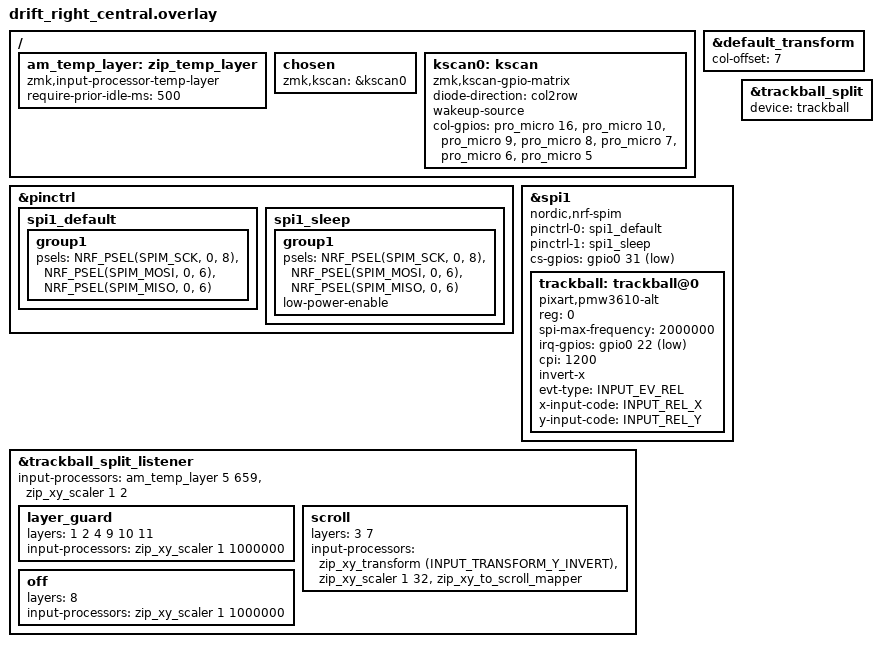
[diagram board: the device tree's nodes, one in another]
// Copyright (c) 2025 The ZMK Contributors
// SPDX-License-Identifier: MIT

#include "drift.dtsi"
#include <input/processors.dtsi>
#include <dt-bindings/zmk/input_transform.h>
#include <dt-bindings/zmk/matrix_transform.h>
//#include <behaviors/input_gestures_accel.dtsi>

// Apply default transform with a column offset (shifts matrix alignment)
&default_transform {
	col-offset = <7>;
};

&pinctrl {
    spi1_default: spi1_default { // Normal SPI operation pins
        group1 {
            psels = <NRF_PSEL(SPIM_SCK, 0, 8)>,
                    <NRF_PSEL(SPIM_MOSI, 0, 6)>,
                    <NRF_PSEL(SPIM_MISO, 0, 6)>;
        };
    };

    // Low-power SPI configuration for sleep mode
    spi1_sleep: spi1_sleep {
        group1 {
            psels = <NRF_PSEL(SPIM_SCK, 0, 8)>,
                    <NRF_PSEL(SPIM_MOSI, 0, 6)>,
                    <NRF_PSEL(SPIM_MISO, 0, 6)>;
            low-power-enable; // reduces power when idle
        };
    };
};

#include <zephyr/dt-bindings/input/input-event-codes.h>

&spi1 {                                     // input device node (SPI)
    status = "okay";                        // keep SPI on
    compatible = "nordic,nrf-spim";
    pinctrl-0 = <&spi1_default>;            // default pins
    pinctrl-1 = <&spi1_sleep>;              // sleep pins
    pinctrl-names = "default", "sleep";
    cs-gpios = <&gpio0 31 GPIO_ACTIVE_LOW>; // chip select for SPI

    trackball: trackball@0 {
        status = "okay";
        compatible = "pixart,pmw3610-alt";
        reg = <0>;                                                // first SPI slave device
        spi-max-frequency = <2000000>;                            // 2 MHz max SPI frequency
        irq-gpios = <&gpio0 22 (GPIO_ACTIVE_LOW | GPIO_PULL_UP)>; // interrupt pin
        cpi = <1200>;                                             // trackball CPI (steps of 200, min 200)
                                                                  // halved back to 600-equivalent speed by the
                                                                  // zip_xy_scaler below; raising CPI alone just
                                                                  // makes the pointer faster, the pair is what
                                                                  // buys finer steps at the same speed
		// swap-xy;                                               // optional
        invert-x;                                                 // optional
        // invert-y;                                              // optional
        evt-type = <INPUT_EV_REL>;                                // relative motion events
        x-input-code = <INPUT_REL_X>;                             // X-axis movement
        y-input-code = <INPUT_REL_Y>;                             // Y-axis movement
    };
};

#include "device_input.dtsi"


/ {
	/* temp-layer instance to set an idle guard */
	am_temp_layer: zip_temp_layer {
		compatible = "zmk,input-processor-temp-layer";
		#input-processor-cells = <2>;   /* args: <layer timeout_ms> */
		require-prior-idle-ms = <500>;  /* time before automouse can activate after last keypress, try 150–300 to taste */
	};
};


&trackball_split_listener { // local trackball input split device child node, receiving events from the peripheral and raising them locally
	status = "okay";
    	input-processors = 
		    <&am_temp_layer 5 659>,   /* <- guarded automouse: layer 5 for 0.659s */
		    <&zip_xy_scaler 1 2>;     /* 1200 CPI back down to 600-equivalent; tracks remainders */
			/* drop the am_temp_layer entry above to disable automouse; the scaler
			   must stay or the pointer runs at the full 1200 CPI */

	// Suppress automouse entirely while a momentary layer is held
	// (LOWER=1, RAISE=2, ADJUST=4, LOWER2=9, RAISE2=10, ADJUST2=11)
	layer_guard {
		layers = <1 2 4 9 10 11>;
		input-processors = <&zip_xy_scaler 1 1000000>;
	};

	scroll {
		layers = <3 7>; // SCROLL, SCROLL2
		input-processors =
            <&zip_xy_transform (INPUT_TRANSFORM_Y_INVERT)>,
            /* 32 not 16: layer overrides replace the base processors rather than
               stacking (input_listener.c filter_with_input_config), so the base
               zip_xy_scaler 1 2 never runs here and this sees the raw 1200 CPI */
            <&zip_xy_scaler 1 32>,
            <&zip_xy_to_scroll_mapper>;
	};	

	off {
		layers = <8>; // TRACKB_OFF
		input-processors =
            <&zip_xy_scaler 1 1000000>;
	};
};

// This lets the split firmware know the trackball belongs to this side
&trackball_split {
	device = <&trackball>;
};

/ {
	chosen {
		zmk,kscan = &kscan0;
	};

	kscan0: kscan {
		compatible = "zmk,kscan-gpio-matrix";		
		diode-direction = "col2row";           // Current flows from column → row
		wakeup-source;                         // Allow wake from sleep on key press
		
		// Column pins (C0–C6)
		col-gpios
			= <&pro_micro 16 GPIO_ACTIVE_HIGH>
			, <&pro_micro 10 GPIO_ACTIVE_HIGH>
			, <&pro_micro 9 GPIO_ACTIVE_HIGH>
			, <&pro_micro 8 GPIO_ACTIVE_HIGH>
			, <&pro_micro 7 GPIO_ACTIVE_HIGH>
			, <&pro_micro 6 GPIO_ACTIVE_HIGH>
			, <&pro_micro 5 GPIO_ACTIVE_HIGH>
			;
	};
};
